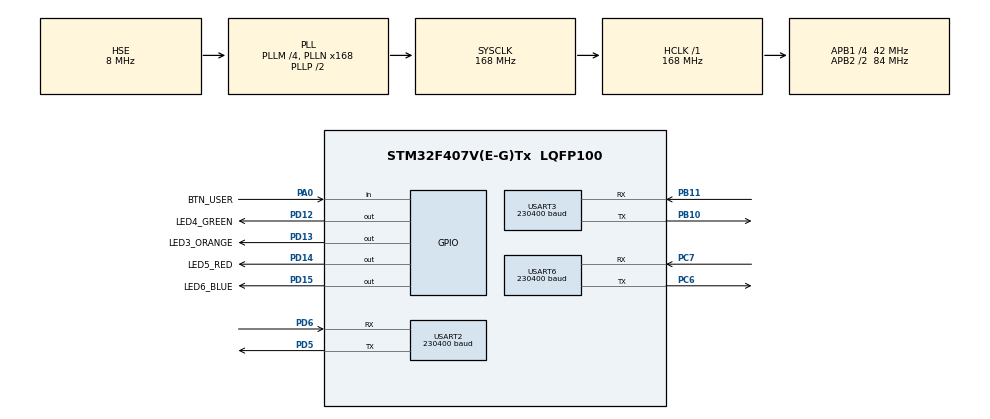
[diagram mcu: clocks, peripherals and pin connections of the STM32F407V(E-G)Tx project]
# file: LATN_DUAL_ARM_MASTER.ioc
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Dma.Request0=USART2_TX
Dma.Request1=USART3_TX
Dma.Request2=USART6_RX
Dma.Request3=USART6_TX
Dma.Request4=USART3_RX
Dma.USART2_TX.0.Direction=DMA_MEMORY_TO_PERIPH
Dma.USART2_TX.0.FIFOMode=DMA_FIFOMODE_DISABLE
Dma.USART2_TX.0.Instance=DMA1_Stream6
Dma.USART2_TX.0.MemDataAlignment=DMA_MDATAALIGN_BYTE
Dma.USART2_TX.0.MemInc=DMA_MINC_ENABLE
Dma.USART2_TX.0.Mode=DMA_NORMAL
Dma.USART2_TX.0.PeriphDataAlignment=DMA_PDATAALIGN_BYTE
Dma.USART2_TX.0.PeriphInc=DMA_PINC_DISABLE
Dma.USART2_TX.0.Priority=DMA_PRIORITY_LOW
Dma.USART3_RX.4.Direction=DMA_PERIPH_TO_MEMORY
Dma.USART3_RX.4.FIFOMode=DMA_FIFOMODE_DISABLE
Dma.USART3_RX.4.Instance=DMA1_Stream1
Dma.USART3_RX.4.MemDataAlignment=DMA_MDATAALIGN_BYTE
Dma.USART3_RX.4.MemInc=DMA_MINC_ENABLE
Dma.USART3_RX.4.Mode=DMA_NORMAL
Dma.USART3_RX.4.PeriphDataAlignment=DMA_PDATAALIGN_BYTE
Dma.USART3_RX.4.PeriphInc=DMA_PINC_DISABLE
Dma.USART3_RX.4.Priority=DMA_PRIORITY_LOW
Dma.USART3_TX.1.Direction=DMA_MEMORY_TO_PERIPH
Dma.USART3_TX.1.FIFOMode=DMA_FIFOMODE_DISABLE
Dma.USART3_TX.1.Instance=DMA1_Stream3
Dma.USART3_TX.1.MemDataAlignment=DMA_MDATAALIGN_BYTE
Dma.USART3_TX.1.MemInc=DMA_MINC_ENABLE
Dma.USART3_TX.1.Mode=DMA_NORMAL
Dma.USART3_TX.1.PeriphDataAlignment=DMA_PDATAALIGN_BYTE
Dma.USART3_TX.1.PeriphInc=DMA_PINC_DISABLE
Dma.USART3_TX.1.Priority=DMA_PRIORITY_LOW
Dma.USART6_RX.2.Direction=DMA_PERIPH_TO_MEMORY
Dma.USART6_RX.2.FIFOMode=DMA_FIFOMODE_DISABLE
Dma.USART6_RX.2.Instance=DMA2_Stream1
Dma.USART6_RX.2.MemDataAlignment=DMA_MDATAALIGN_BYTE
Dma.USART6_RX.2.MemInc=DMA_MINC_ENABLE
Dma.USART6_RX.2.Mode=DMA_NORMAL
Dma.USART6_RX.2.PeriphDataAlignment=DMA_PDATAALIGN_BYTE
Dma.USART6_RX.2.PeriphInc=DMA_PINC_DISABLE
Dma.USART6_RX.2.Priority=DMA_PRIORITY_LOW
Dma.USART6_TX.3.Direction=DMA_MEMORY_TO_PERIPH
Dma.USART6_TX.3.FIFOMode=DMA_FIFOMODE_DISABLE
Dma.USART6_TX.3.Instance=DMA2_Stream6
Dma.USART6_TX.3.MemDataAlignment=DMA_MDATAALIGN_BYTE
Dma.USART6_TX.3.MemInc=DMA_MINC_ENABLE
Dma.USART6_TX.3.Mode=DMA_NORMAL
Dma.USART6_TX.3.PeriphDataAlignment=DMA_PDATAALIGN_BYTE
Dma.USART6_TX.3.PeriphInc=DMA_PINC_DISABLE
Dma.USART6_TX.3.Priority=DMA_PRIORITY_LOW
Mcu.Family=STM32F4
Mcu.Name=STM32F407V(E-G)Tx
Mcu.Package=LQFP100
NVIC.DMA1_Stream1_IRQn=true\:0\:0\:false\:false\:true\:false\:true\:true
NVIC.DMA1_Stream3_IRQn=true\:0\:0\:false\:false\:true\:false\:true\:true
NVIC.DMA1_Stream6_IRQn=true\:0\:0\:false\:false\:true\:false\:true\:true
NVIC.DMA2_Stream1_IRQn=true\:0\:0\:false\:false\:true\:false\:true\:true
NVIC.DMA2_Stream6_IRQn=true\:0\:0\:false\:false\:true\:false\:true\:true
NVIC.PriorityGroup=NVIC_PRIORITYGROUP_0
NVIC.TIM2_IRQn=true\:0\:0\:false\:false\:true\:true\:true\:true
NVIC.USART2_IRQn=true\:0\:0\:false\:false\:true\:true\:true\:true
NVIC.USART3_IRQn=true\:0\:0\:false\:false\:true\:true\:true\:true
NVIC.USART6_IRQn=true\:0\:0\:false\:false\:true\:true\:true\:true
PA0-WKUP.GPIO_Label=BTN_USER
PA0-WKUP.Signal=GPIO_Input
PA13.Mode=Serial_Wire
PA13.Signal=SYS_JTMS-SWDIO
PA14.Mode=Serial_Wire
PA14.Signal=SYS_JTCK-SWCLK
PB10.Mode=Asynchronous
PB10.Signal=USART3_TX
PB11.Mode=Asynchronous
PB11.Signal=USART3_RX
PC6.Mode=Asynchronous
PC6.Signal=USART6_TX
PC7.Mode=Asynchronous
PC7.Signal=USART6_RX
PD12.GPIO_Label=LED4_GREEN
PD12.Signal=GPIO_Output
PD13.GPIO_Label=LED3_ORANGE
PD13.Signal=GPIO_Output
PD14.GPIO_Label=LED5_RED
PD14.Signal=GPIO_Output
PD15.GPIO_Label=LED6_BLUE
PD15.Signal=GPIO_Output
PD5.Mode=Asynchronous
PD5.Signal=USART2_TX
PD6.Mode=Asynchronous
PD6.Signal=USART2_RX
PH0-OSC_IN.Mode=HSE-External-Oscillator
PH0-OSC_IN.Signal=RCC_OSC_IN
PH1-OSC_OUT.Mode=HSE-External-Oscillator
PH1-OSC_OUT.Signal=RCC_OSC_OUT
ProjectManager.HeapSize=0x200
ProjectManager.StackSize=0x400
ProjectManager.TargetToolchain=STM32CubeIDE
RCC.48MHZClocksFreq_Value=48000000
RCC.AHBFreq_Value=168000000
RCC.APB1CLKDivider=RCC_HCLK_DIV4
RCC.APB1Freq_Value=42000000
RCC.APB1TimFreq_Value=84000000
RCC.APB2CLKDivider=RCC_HCLK_DIV2
RCC.APB2Freq_Value=84000000
RCC.APB2TimFreq_Value=168000000
RCC.CortexFreq_Value=168000000
RCC.HCLKFreq_Value=168000000
RCC.HSE_VALUE=8000000
RCC.HSI_VALUE=16000000
RCC.LSE_VALUE=32768
RCC.PLLM=4
RCC.PLLN=168
RCC.PLLQ=7
RCC.PLLSourceVirtual=RCC_PLLSOURCE_HSE
RCC.SYSCLKFreq_VALUE=168000000
RCC.SYSCLKSource=RCC_SYSCLKSOURCE_PLLCLK
RCC.VCOOutputFreq_Value=336000000
TIM2.Period=100-1
TIM2.Prescaler=8400-1
USART2.BaudRate=230400
USART2.Mode=MODE_TX
USART2.VirtualMode=VM_ASYNC
USART3.BaudRate=230400
USART3.VirtualMode=VM_ASYNC
USART6.BaudRate=230400
USART6.VirtualMode=VM_ASYNC
VP_TIM2_VS_ClockSourceINT.Mode=Internal
board=STM32F407G-DISC1

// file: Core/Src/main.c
/* USER CODE BEGIN Header */
/**
  ******************************************************************************
  * @file           : main.c
  * @brief          : Main program body
  ******************************************************************************
  * @attention
  *
  * Copyright (c) 2024 STMicroelectronics.
  * All rights reserved.
  *
  * This software is licensed under terms that can be found in the LICENSE file
  * in the root directory of this software component.
  * If no LICENSE file comes with this software, it is provided AS-IS.
  *
  ******************************************************************************
  */
/* USER CODE END Header */
#include "main.h"

/* USER CODE BEGIN Includes */
#include "LibraryHHInterface_Master.h"
/* USER CODE END Includes */

TIM_HandleTypeDef htim2;

UART_HandleTypeDef huart2;
UART_HandleTypeDef huart3;
UART_HandleTypeDef huart6;
DMA_HandleTypeDef hdma_usart2_tx;
DMA_HandleTypeDef hdma_usart3_tx;
DMA_HandleTypeDef hdma_usart3_rx;
DMA_HandleTypeDef hdma_usart6_rx;
DMA_HandleTypeDef hdma_usart6_tx;

void SystemClock_Config(void);
static void MX_GPIO_Init(void);
static void MX_DMA_Init(void);
static void MX_USART2_UART_Init(void);
static void MX_USART3_UART_Init(void);
static void MX_USART6_UART_Init(void);
static void MX_TIM2_Init(void);
/* USER CODE BEGIN PFP */
//PRIVATE U08 TxData[10] = {49,50,51,52,53,54,55,56,57,48};
/* USER CODE END PFP */

int main(void)
{

  /* USER CODE BEGIN 1 */
	/* Enable floating point unit (FPU) for speeding up float value calculation
	 * Note:
	 * 	1/ FPU in Stm32F407 support only Float type, not Double type
	 * 	2/ Enable FPU at compile-time: Properties -> C/C++ Build -> Settings -> MCU/MPU Settings:
	 * 		- Floating-point unit: FPv4-SP-D16
	 * 		- Floating-point ABI:  Hardware Implementation (-mfloat-api=hard)
	 * 	3/ Enable FPU enable in code:
	 * 		- SCB->CPACR |= (0xF << 20);
	 * */
	SCB->CPACR |= (0xF << 20);
  /* USER CODE END 1 */

  /* MCU Configuration--------------------------------------------------------*/

  /* Reset of all peripherals, Initializes the Flash interface and the Systick. */
  HAL_Init();

  /* Configure the system clock */
  SystemClock_Config();

  /* Initialize all configured peripherals */
  MX_GPIO_Init();
  MX_DMA_Init();
  MX_USART2_UART_Init();
  MX_USART3_UART_Init();
  MX_USART6_UART_Init();
  MX_TIM2_Init();
  /* USER CODE BEGIN 2 */
  AppCommUART_UserSetup(&huart6, UART_NODE_SLAVE_1);
  AppCommUART_UserSetup(&huart2, UART_NODE_GUI);
  AppCommUART_UserSetup(&huart3, UART_NODE_SLAVE_2);
  /* USER CODE END 2 */

  /* Infinite loop */
  /* USER CODE BEGIN WHILE */
  HAL_TIM_Base_Start_IT(&htim2);	// Cycle 10ms
  while (1)
  {
	AppPeriodTask_StateMachineProcess();

    /* USER CODE END WHILE */

  }
}

void SystemClock_Config(void)
{
  RCC_OscInitTypeDef RCC_OscInitStruct = {0};
  RCC_ClkInitTypeDef RCC_ClkInitStruct = {0};

  /** Configure the main internal regulator output voltage
  */
  __HAL_RCC_PWR_CLK_ENABLE();
  __HAL_PWR_VOLTAGESCALING_CONFIG(PWR_REGULATOR_VOLTAGE_SCALE1);

  /** Initializes the RCC Oscillators according to the specified parameters
  * in the RCC_OscInitTypeDef structure.
  */
  RCC_OscInitStruct.OscillatorType = RCC_OSCILLATORTYPE_HSE;
  RCC_OscInitStruct.HSEState = RCC_HSE_ON;
  RCC_OscInitStruct.PLL.PLLState = RCC_PLL_ON;
  RCC_OscInitStruct.PLL.PLLSource = RCC_PLLSOURCE_HSE;
  RCC_OscInitStruct.PLL.PLLM = 4;
  RCC_OscInitStruct.PLL.PLLN = 168;
  RCC_OscInitStruct.PLL.PLLP = RCC_PLLP_DIV2;
  RCC_OscInitStruct.PLL.PLLQ = 7;
  if (HAL_RCC_OscConfig(&RCC_OscInitStruct) != HAL_OK)
  {
    Error_Handler();
  }

  /** Initializes the CPU, AHB and APB buses clocks
  */
  RCC_ClkInitStruct.ClockType = RCC_CLOCKTYPE_HCLK|RCC_CLOCKTYPE_SYSCLK
                              |RCC_CLOCKTYPE_PCLK1|RCC_CLOCKTYPE_PCLK2;
  RCC_ClkInitStruct.SYSCLKSource = RCC_SYSCLKSOURCE_PLLCLK;
  RCC_ClkInitStruct.AHBCLKDivider = RCC_SYSCLK_DIV1;
  RCC_ClkInitStruct.APB1CLKDivider = RCC_HCLK_DIV4;
  RCC_ClkInitStruct.APB2CLKDivider = RCC_HCLK_DIV2;

  if (HAL_RCC_ClockConfig(&RCC_ClkInitStruct, FLASH_LATENCY_5) != HAL_OK)
  {
    Error_Handler();
  }
}

static void MX_TIM2_Init(void)
{

  TIM_ClockConfigTypeDef sClockSourceConfig = {0};
  TIM_MasterConfigTypeDef sMasterConfig = {0};

  htim2.Instance = TIM2;
  htim2.Init.Prescaler = 8400-1;
  htim2.Init.CounterMode = TIM_COUNTERMODE_UP;
  htim2.Init.Period = 100-1;
  htim2.Init.ClockDivision = TIM_CLOCKDIVISION_DIV1;
  htim2.Init.AutoReloadPreload = TIM_AUTORELOAD_PRELOAD_DISABLE;
  if (HAL_TIM_Base_Init(&htim2) != HAL_OK)
  {
    Error_Handler();
  }
  sClockSourceConfig.ClockSource = TIM_CLOCKSOURCE_INTERNAL;
  if (HAL_TIM_ConfigClockSource(&htim2, &sClockSourceConfig) != HAL_OK)
  {
    Error_Handler();
  }
  sMasterConfig.MasterOutputTrigger = TIM_TRGO_RESET;
  sMasterConfig.MasterSlaveMode = TIM_MASTERSLAVEMODE_DISABLE;
  if (HAL_TIMEx_MasterConfigSynchronization(&htim2, &sMasterConfig) != HAL_OK)
  {
    Error_Handler();
  }

}

static void MX_USART2_UART_Init(void)
{

  huart2.Instance = USART2;
  huart2.Init.BaudRate = 230400;
  huart2.Init.WordLength = UART_WORDLENGTH_8B;
  huart2.Init.StopBits = UART_STOPBITS_1;
  huart2.Init.Parity = UART_PARITY_NONE;
  huart2.Init.Mode = UART_MODE_TX;
  huart2.Init.HwFlowCtl = UART_HWCONTROL_NONE;
  huart2.Init.OverSampling = UART_OVERSAMPLING_16;
  if (HAL_UART_Init(&huart2) != HAL_OK)
  {
    Error_Handler();
  }

}

static void MX_USART3_UART_Init(void)
{

  huart3.Instance = USART3;
  huart3.Init.BaudRate = 230400;
  huart3.Init.WordLength = UART_WORDLENGTH_8B;
  huart3.Init.StopBits = UART_STOPBITS_1;
  huart3.Init.Parity = UART_PARITY_NONE;
  huart3.Init.Mode = UART_MODE_TX_RX;
  huart3.Init.HwFlowCtl = UART_HWCONTROL_NONE;
  huart3.Init.OverSampling = UART_OVERSAMPLING_16;
  if (HAL_UART_Init(&huart3) != HAL_OK)
  {
    Error_Handler();
  }

}

static void MX_USART6_UART_Init(void)
{

  huart6.Instance = USART6;
  huart6.Init.BaudRate = 230400;
  huart6.Init.WordLength = UART_WORDLENGTH_8B;
  huart6.Init.StopBits = UART_STOPBITS_1;
  huart6.Init.Parity = UART_PARITY_NONE;
  huart6.Init.Mode = UART_MODE_TX_RX;
  huart6.Init.HwFlowCtl = UART_HWCONTROL_NONE;
  huart6.Init.OverSampling = UART_OVERSAMPLING_16;
  if (HAL_UART_Init(&huart6) != HAL_OK)
  {
    Error_Handler();
  }

}

static void MX_DMA_Init(void)
{

  /* DMA controller clock enable */
  __HAL_RCC_DMA1_CLK_ENABLE();
  __HAL_RCC_DMA2_CLK_ENABLE();

  /* DMA interrupt init */
  /* DMA1_Stream1_IRQn interrupt configuration */
  HAL_NVIC_SetPriority(DMA1_Stream1_IRQn, 0, 0);
  HAL_NVIC_EnableIRQ(DMA1_Stream1_IRQn);
  /* DMA1_Stream3_IRQn interrupt configuration */
  HAL_NVIC_SetPriority(DMA1_Stream3_IRQn, 0, 0);
  HAL_NVIC_EnableIRQ(DMA1_Stream3_IRQn);
  /* DMA1_Stream6_IRQn interrupt configuration */
  HAL_NVIC_SetPriority(DMA1_Stream6_IRQn, 0, 0);
  HAL_NVIC_EnableIRQ(DMA1_Stream6_IRQn);
  /* DMA2_Stream1_IRQn interrupt configuration */
  HAL_NVIC_SetPriority(DMA2_Stream1_IRQn, 0, 0);
  HAL_NVIC_EnableIRQ(DMA2_Stream1_IRQn);
  /* DMA2_Stream6_IRQn interrupt configuration */
  HAL_NVIC_SetPriority(DMA2_Stream6_IRQn, 0, 0);
  HAL_NVIC_EnableIRQ(DMA2_Stream6_IRQn);

}

static void MX_GPIO_Init(void)
{
  GPIO_InitTypeDef GPIO_InitStruct = {0};

  /* GPIO Ports Clock Enable */
  __HAL_RCC_GPIOH_CLK_ENABLE();
  __HAL_RCC_GPIOA_CLK_ENABLE();
  __HAL_RCC_GPIOB_CLK_ENABLE();
  __HAL_RCC_GPIOD_CLK_ENABLE();
  __HAL_RCC_GPIOC_CLK_ENABLE();

  /*Configure GPIO pin Output Level */
  HAL_GPIO_WritePin(GPIOD, LED4_GREEN_Pin|LED3_ORANGE_Pin|LED5_RED_Pin|LED6_BLUE_Pin, GPIO_PIN_RESET);

  /*Configure GPIO pin : BTN_USER_Pin */
  GPIO_InitStruct.Pin = BTN_USER_Pin;
  GPIO_InitStruct.Mode = GPIO_MODE_INPUT;
  GPIO_InitStruct.Pull = GPIO_NOPULL;
  HAL_GPIO_Init(BTN_USER_GPIO_Port, &GPIO_InitStruct);

  /*Configure GPIO pins : LED4_GREEN_Pin LED3_ORANGE_Pin LED5_RED_Pin LED6_BLUE_Pin */
  GPIO_InitStruct.Pin = LED4_GREEN_Pin|LED3_ORANGE_Pin|LED5_RED_Pin|LED6_BLUE_Pin;
  GPIO_InitStruct.Mode = GPIO_MODE_OUTPUT_PP;
  GPIO_InitStruct.Pull = GPIO_NOPULL;
  GPIO_InitStruct.Speed = GPIO_SPEED_FREQ_LOW;
  HAL_GPIO_Init(GPIOD, &GPIO_InitStruct);

}

void Error_Handler(void)
{
  __disable_irq();
  while (1)
  {
  }
}
